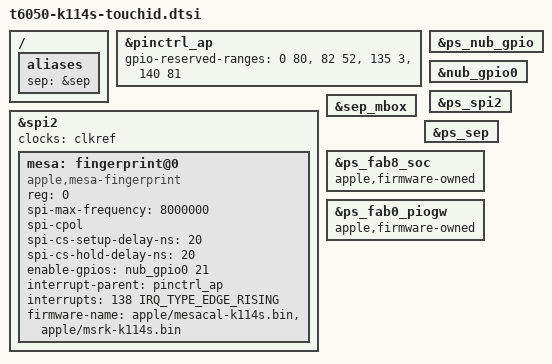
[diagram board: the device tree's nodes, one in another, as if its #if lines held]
// SPDX-License-Identifier: GPL-2.0+ OR MIT
/*
 * K114s: Touch ID. The Mesa fingerprint sensor on spi2 and the Secure Enclave (SEP) nodes that
 * the aurora-sep driver needs. Included, switched on, by the trial tree t6050-k114s-r3b-touchid.dts
 * only (docs/r3-touchid.md, issue #49). NOT booted on a K114s yet.
 *
 * Copy of the J714s nodes of aurora-silicon/linux #1587 (merged 2026-11-12, validated there by
 * enrolling and matching on a J714s) and of the K116s SEP block of #1648. Every value equals this
 * Mac's ADT (tests/k114s-adt-touchid-facts.py, agent-run 2026-11-15):
 *   sensor        /arm-io/spi2/mesa  sensor-id 0x3356, spi-frequency 8 000 000
 *   controller    spi2 reg 0x505108000 + 0x4000, interrupt 1369, clock-ids 451 (the 24 MHz reference)
 *   power         mesa function-mesa_pwr: nub-gpio0 pin 21 (always-on bank 0x2881e4000, 61 pins)
 *   data ready    mesa interrupts: gpio0 (AP bank) pin 138, edge
 *   SEP           sep reg 0x502600000 and 0x502050000; interrupts 533 to 536; clock-ids 447;
 *                 dart-sep 0x500b80000, interrupt 543, window 0x10000004000 + 0xffff0000
 * The base kernel tree already has spi2, nub_gpio0, ps_nub_gpio, ps_spi2, sep, sep_mbox, sep_dart
 * and ps_sep, all disabled; this file turns them on and adds the sensor node.
 *
 * What this file does NOT do, and what else is needed:
 *   - the apple_sep driver upstream does not admit a K114s. Its T6050 profile matches apple,j714s
 *     and apple,k116s only (drivers/soc/apple/profile.rs, aurora-silicon/linux #1649 added the
 *     K116s). patches/linux/sep/0001 (kernel r3b.c4) adds apple,k114s; other kernels refuse.
 *   - /aliases/sep is not in the booted tree. The K116s tree has `sep = &sep;`, so the alias is added
 *     here; whether our m1n1 acts on it is unverified (phase 3 trial boot).
 *   - omarchy-mac's touchid-eligibility lists no T6050 board and answers "unsupported:board".
 *   - the calibration and sensor root key names below are the J714s pattern; the setup tool
 *     (aurora-touchid-setup) carves them from this Mac's own iBoot System Container. Not run.
 *   - Enabling the SEP driver with its default options writes Secure Enclave and xART state that
 *     macOS shares. Owner decision, backups and a trial boot: see docs/r3-touchid.md.
 *
 * Pin 138 is exposed through gpio-reserved-ranges, as #1587 does for the J714s: while it is
 * reserved gpiolib refuses the interrupt (rc=-6). Pin 112 stays reserved (SError on read). This
 * file replaces gpio-reserved-ranges, so it carries the pins of the other fragments through two
 * switches: K114S_TOUCHID_WITH_SD (80, 81, 138 exposed) and K114S_TOUCHID_WITH_SOUND (80, 81,
 * 134, 138, 139 exposed; covers the SD reader too). With neither: 80 and 138.
 *
 * Include order: this file replaces gpio-reserved-ranges, so include it after t6050-k114s-sd.dtsi
 * and t6050-k114s-sound.dtsi (the later one wins).
 *
 * Define K114S_R3_TOUCHID to turn it on. Without it this file changes nothing.
 */
#ifdef K114S_R3_TOUCHID

/ {
	aliases {
		sep = &sep;
	};
};

&pinctrl_ap {
#if defined(K114S_TOUCHID_WITH_SOUND)
	gpio-reserved-ranges = <0 80>, <82 52>, <135 3>, <140 81>;
#elif defined(K114S_TOUCHID_WITH_SD)
	gpio-reserved-ranges = <0 80>, <82 56>, <139 82>;
#else
	gpio-reserved-ranges = <0 80>, <81 57>, <139 82>;
#endif
};

/* The always-on GPIO bank that switches the sensor's power (61 pins) */
&ps_nub_gpio {
	status = "okay";
};

&nub_gpio0 {
	status = "okay";
};

&ps_spi2 {
	status = "okay";
};

/* The controller's clock (ADT clock-ids 451) is the 24 MHz reference; its PMGR provider has no driver */
&spi2 {
	clocks = <&clkref>;
	status = "okay";

	mesa: fingerprint@0 {
		compatible = "apple,mesa-fingerprint";
		reg = <0>;
		spi-max-frequency = <8000000>;
		spi-cpol;
		spi-cs-setup-delay-ns = <20>;
		spi-cs-hold-delay-ns = <20>;
		enable-gpios = <&nub_gpio0 21 GPIO_ACTIVE_HIGH>;
		interrupt-parent = <&pinctrl_ap>;
		interrupts = <138 IRQ_TYPE_EDGE_RISING>;
		/* Per-device factory data from this Mac's own iBoot System Container (names: J714s pattern, unverified) */
		firmware-name = "apple/mesacal-k114s.bin", "apple/msrk-k114s.bin";
	};
};

/*
 * The SEP, as in the K116s tree: its mailbox and its power domain, with the two fabric parents
 * left to the firmware (genpd votes on them and never turns them off). The sep and sep_dart nodes
 * stay disabled; apple_sep enables them when it loads.
 */
&sep_mbox {
	status = "okay";
};

&ps_sep {
	status = "okay";
};

&ps_fab8_soc {
	apple,firmware-owned;
	status = "okay";
};

&ps_fab0_piogw {
	apple,firmware-owned;
	status = "okay";
};

#endif /* K114S_R3_TOUCHID */
